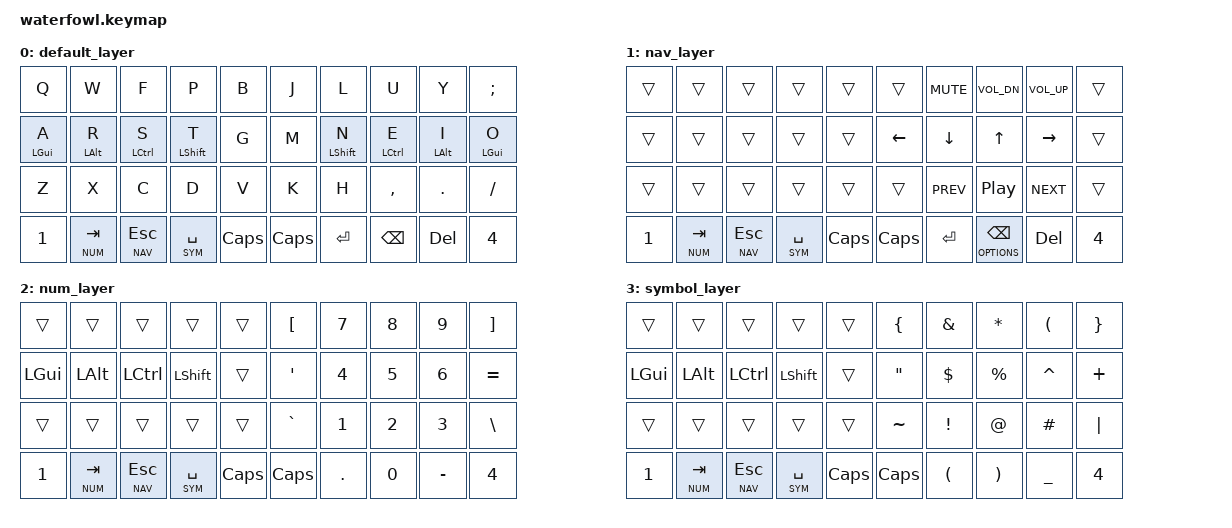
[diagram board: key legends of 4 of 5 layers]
/*
 * Copyright (c) 2022 The ZMK Contributors
 *
 * SPDX-License-Identifier: MIT
 */

#include <behaviors.dtsi>
#include <dt-bindings/zmk/keys.h>
#include <dt-bindings/zmk/bt.h>
#define DEFAULT 0
#define NAV     1
#define NUM     2
#define SYM     3
#define OPTIONS 4

/ {
  behaviors {
      hm: homerow_mods {
          compatible = "zmk,behavior-hold-tap";
          label = "HOMEROW_MODS";
          #binding-cells = <2>;
          tapping-term-ms = <150>;
          quick-tap-ms = <0>;
          flavor = "tap-preferred";
          bindings = <&kp>, <&kp>;
      };
  };

	keymap {
		compatible = "zmk,keymap";

		default_layer {
/* QWERTY
 *
 * ,----------------------------------.                      ,----------------------------------.
 * |   Q  |   W  |   F  |   P  |   B  |                      |   J  |   L  |   U  |   Y  |   ;  |
 * |------+------+------+------+------|                      |------+------+------+------+------|
 * |   A  |   R  |   S  |   T  |   G  |                      |   M  |   N  |   E  |   I  |   O  |
 * |------+------+------+------+------|  ,-----.    ,-----.  |------+------+------+------+------|
 * |   Z  |   X  |   C  |   D  |   V  |  |CAPS |    |CAPS |  |   K  |   H  |   ,  |   .  |   /  |
 * `----------------------------------'  `-----'    `-----'  `----------------------------------'
 *          ,-----.   ,--------------------.            ,--------------------.   ,-----. 
 *          |  1  |   | TAB | ESC | SPACE  |            |  ENTER  | BS | DEL |   |  4  |	
 *          `-----'   `--------------------'            `--------------------'   `-----'
 */
			bindings = <
  &kp Q       &kp W       &kp F        &kp P        &kp B     &kp J  &kp L        &kp U            &kp Y         &kp SEMI
  &hm LGUI A  &hm LALT R  &hm LCTRL S  &hm LSHFT T  &kp G     &kp M  &hm LSHFT N  &hm LCTRL E      &hm LALT I    &hm LGUI O
  &kp Z       &kp X       &kp C        &kp D        &kp V     &kp K  &kp H        &kp COMMA        &kp DOT       &kp FSLH
  &kp N1 &lt NUM TAB  &lt NAV ESC  &lt SYM SPACE &kp CLCK     &kp CLCK &kp RET  &kp BSPC  &kp DEL	&kp N4
			>;

			sensor-bindings = <&inc_dec_kp PAGE_UP PAGE_DOWN &inc_dec_kp TAB LS(TAB)>;
		};

		nav_layer {
/* NAV
 *
 * ,----------------------------------.                      ,----------------------------------.
 * |      |      |      |      |      |                      |      | MUT  |  VO- | VO+  |      |
 * |------+------+------+------+------|                      |------+------+------+------+------|
 * |      |      |      |      |      |                      | LEFT | DOWN |  UP  |RIGHT |      |
 * |------+------+------+------+------|  ,-----.    ,-----.  |------+------+------+------+------|
 * |      |      |      |      |      |  |CAPS |    |NUMLK|  |      | PREV | PLAY | NEXT |      |
 * `----------------------------------'  `-----'    `-----'  `----------------------------------'
 *          ,-----.   ,--------------------.            ,--------------------.   ,-----. 
 *          |  1  |   | TAB | ESC | SPACE  |            |  ENTER  | BS | DEL |   |  4  |	
 *          `-----'   `--------------------'            `--------------------'   `-----'
 */
			bindings = <
  &trans  &trans  &trans  &trans  &trans       &trans        &kp K_MUTE    &kp C_VOL_DN  &kp C_VOL_UP    &trans
  &trans  &trans  &trans  &trans  &trans       &kp LEFT      &kp DOWN      &kp UP        &kp RIGHT       &trans
  &trans  &trans  &trans  &trans  &trans       &trans        &kp C_PREV    &kp C_PP      &kp C_NEXT      &trans
  &kp N1 &lt NUM TAB  &lt NAV ESC  &lt SYM SPACE &kp CLCK    &kp CLCK &kp RET  &lt OPTIONS BSPC  &kp DEL	&kp N4
			>;

			sensor-bindings = <&inc_dec_kp PAGE_UP PAGE_DOWN &inc_dec_kp TAB LS(TAB)>;
		};

		num_layer {
/* NUM
 *
 * ,----------------------------------.                      ,----------------------------------.
 * |      |      |      |      |      |                      |   [  |   7  |   8  |   9  |   ]  |
 * |------+------+------+------+------|                      |------+------+------+------+------|
 * |  GUI |  ALT | CTRL |SHIFT |      |                      |   '  |   4  |   5  |   6  |   =  |
 * |------+------+------+------+------|  ,-----.    ,-----.  |------+------+------+------+------|
 * |      |      |      |      |      |  |CAPS |    |NUMLK|  |   `  |   1  |   2  |   3  |   \  |
 * `----------------------------------'  `-----'    `-----'  `----------------------------------'
 *          ,-----.   ,--------------------.            ,--------------------.   ,-----. 
 *          |  1  |   | TAB | ESC | SPACE  |            |  ENTER  | BS | DEL |   |  4  |	
 *          `-----'   `--------------------'            `--------------------'   `-----'
 */
			bindings = <
  &trans    &trans    &trans     &trans     &trans             &kp LBKT   &kp N7   &kp N8   &kp N9   &kp RBKT
  &kp LGUI  &kp LALT  &kp LCTRL  &kp LSHFT  &trans             &kp SQT    &kp N4   &kp N5   &kp N6   &kp EQUAL
  &trans    &trans    &trans     &trans     &trans             &kp GRAVE  &kp N1   &kp N2   &kp N3   &kp BSLH
  &kp N1  &lt NUM TAB  &lt NAV ESC  &lt SYM SPACE  &kp CLCK    &kp CLCK  &kp DOT  &kp N0  &kp MINUS	&kp N4
			>;

			sensor-bindings = <&inc_dec_kp PAGE_UP PAGE_DOWN &inc_dec_kp TAB LS(TAB)>;
		};
		symbol_layer {
/* SYM
 *
 * ,----------------------------------.                      ,----------------------------------.
 * |      |      |      |      |      |                      |   {  |   &  |   *  |   (  |   }  |
 * |------+------+------+------+------|                      |------+------+------+------+------|
 * |  GUI |  ALT | CTRL |SHIFT |      |                     |   "  |   $  |   %  |   ^  |   +  |
 * |------+------+------+------+------|  ,-----.    ,-----.  |------+------+------+------+------|
 * |      |      |      |      |      |  |CAPS |    |NUMLK|  |   ~  |   !  |   @  |   #  |   |  |
 * `----------------------------------'  `-----'    `-----'  `----------------------------------'
 *          ,-----.   ,--------------------.            ,--------------------.   ,-----. 
 *          |  1  |   | TAB | ESC | SPACE  |            |  ENTER  | BS | DEL |   |  4  |	
 *          `-----'   `--------------------'            `--------------------'   `-----'
 */
			bindings = <
  &trans    &trans    &trans     &trans     &trans             &kp LBRC   &kp AMPS  &kp STAR   &kp LPAR   &kp RBRC
  &kp LGUI  &kp LALT  &kp LCTRL  &kp LSHFT  &trans             &kp DQT    &kp DLLR  &kp PRCNT  &kp CARET  &kp PLUS
  &trans    &trans    &trans     &trans     &trans             &kp TILDE  &kp EXCL  &kp AT     &kp HASH   &kp PIPE
  &kp N1  &lt NUM TAB  &lt NAV ESC  &lt SYM SPACE  &kp CLCK    &kp CLCK  &kp LPAR  &kp RPAR  &kp UNDER  &kp N4
			>;

			sensor-bindings = <&inc_dec_kp PAGE_UP PAGE_DOWN &inc_dec_kp TAB LS(TAB)>;
		};

		function_layer {
/* FUNC
 *
 * ,----------------------------------.                      ,----------------------------------.
 * |      |      | BTCLR|      |      |                      |      |  F1  |  F2  |  F3  |  F4  |
 * |------+------+------+------+------|                      |------+------+------+------+------|
 * |  BT0 |  BT1 |  BT2 |  BT3 |  BT4 |                      |      |  F5  |  F6  |  F7  |  F8  |
 * |------+------+------+------+------|  ,-----.    ,-----.  |------+------+------+------+------|
 * |      |      |      |      |      |  |CAPS |    |NUMLK|  |      |  F9  |  F10 |  F11 |  F12 |
 * `----------------------------------'  `-----'    `-----'  `----------------------------------'
 *          ,-----.   ,--------------------.            ,--------------------.   ,-----. 
 *          |  1  |   | TAB | ESC | SPACE  |            |  ENTER  | BS | DEL |   |  4  |	
 *          `-----'   `--------------------'            `--------------------'   `-----'
 */
			bindings = <
  &trans        &trans        &bt BT_CLR    &trans  &trans     &trans  &kp F1  &kp F2   &kp F3   &kp F4
  &bt BT_SEL 0  &bt BT_SEL 1  &bt BT_SEL 2  &trans  &trans     &trans  &kp F5  &kp F6   &kp F7   &kp F8
  &trans        &trans        &trans        &trans  &trans     &trans  &kp F9  &kp F10  &kp F11  &kp F12
                &trans        &trans        &trans  &trans     &trans  &trans  &trans   &trans 
			>;

			sensor-bindings = <&inc_dec_kp PAGE_UP PAGE_DOWN &inc_dec_kp TAB LS(TAB)>;
		};	

	};
};
